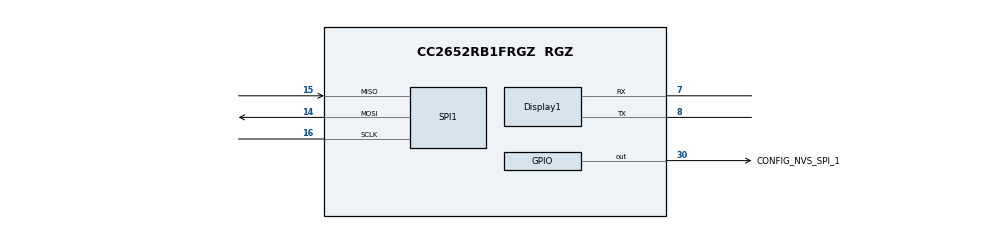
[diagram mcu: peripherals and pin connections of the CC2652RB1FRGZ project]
/**
 * @cliArgs --device "CC2652RB1FRGZ" --package "RGZ" --part "Default" --product "simplelink_cc13x2_26x2_sdk@5.10.00.48"
 * @versions {"data":"2021031521","timestamp":"2021031521","tool":"1.8.0+1863","templates":null}
 */

/**
 * Import the modules used in this configuration.
 */
const CCFG      = scripting.addModule("/ti/devices/CCFG");
const rfdesign  = scripting.addModule("/ti/devices/radioconfig/rfdesign");
const Display   = scripting.addModule("/ti/display/Display", {}, false);
const Display1  = Display.addInstance();
const AESCCM    = scripting.addModule("/ti/drivers/AESCCM");
const AESCCM1   = AESCCM.addInstance();
const AESECB    = scripting.addModule("/ti/drivers/AESECB");
const AESECB1   = AESECB.addInstance();
const Board     = scripting.addModule("/ti/drivers/Board");
const DMA       = scripting.addModule("/ti/drivers/DMA");
const ECDH      = scripting.addModule("/ti/drivers/ECDH");
const ECDH1     = ECDH.addInstance();
const ECDSA     = scripting.addModule("/ti/drivers/ECDSA");
const ECDSA1    = ECDSA.addInstance();
const ECJPAKE   = scripting.addModule("/ti/drivers/ECJPAKE");
const ECJPAKE1  = ECJPAKE.addInstance();
const NVS       = scripting.addModule("/ti/drivers/NVS");
const NVS1      = NVS.addInstance();
const NVS2      = NVS.addInstance();
const Power     = scripting.addModule("/ti/drivers/Power");
const RF        = scripting.addModule("/ti/drivers/RF");
const SHA2      = scripting.addModule("/ti/drivers/SHA2");
const SHA21     = SHA2.addInstance();
const SPI       = scripting.addModule("/ti/drivers/SPI", {}, false);
const SPI1      = SPI.addInstance();
const TRNG      = scripting.addModule("/ti/drivers/TRNG");
const TRNG1     = TRNG.addInstance();
const Watchdog  = scripting.addModule("/ti/drivers/Watchdog");
const Watchdog1 = Watchdog.addInstance();
const thread    = scripting.addModule("/ti/thread/thread");
const JSON      = scripting.addModule("/ti/utils/JSON");

/**
 * Write custom configuration values to the imported modules.
 */
CCFG.enableBootloader         = true;
CCFG.enableBootloaderBackdoor = true;
CCFG.dioBootloaderBackdoor    = 13;
CCFG.levelBootloaderBackdoor  = "Active low";
CCFG.srcClkLF                 = "LF RCOSC";
CCFG.enableCodeGeneration     = false;
CCFG.ccfgTemplate.$name       = "ti_devices_CCFGTemplateInit0";

Display1.$name                    = "CONFIG_DISPLAY_UART";
Display1.uart.$name               = "CONFIG_UART_0";
Display1.uart.uart.txPin.$assign  = "8";
Display1.uart.uart.rxPin.$assign  = "7";
Display1.uart.txPinInstance.$name = "CONFIG_PIN_1";
Display1.uart.rxPinInstance.$name = "CONFIG_PIN_2";

AESCCM1.$name = "CONFIG_AESCCM_0";

AESECB1.$name = "CONFIG_AESECB_0";

Board.generateInitializationFunctions = false;

ECDH1.$name = "CONFIG_ECDH_0";

ECDSA1.$name = "CONFIG_ECDSA_0";

ECJPAKE1.$name = "CONFIG_ECJPAKE_0";

NVS1.$name                    = "CONFIG_NVSINTERNAL";
NVS1.internalFlash.$name      = "ti_drivers_nvs_NVSCC26XX0";
NVS1.internalFlash.regionBase = 0x52000;
NVS1.internalFlash.regionSize = 0x4000;

NVS2.$name                          = "CONFIG_NVS_EXTERNAL";
NVS2.nvsType                        = "External";
NVS2.externalFlash.$name            = "ti_drivers_nvs_NVSSPI25X1";
NVS2.externalFlash.regionSize       = 0x128000;
NVS2.externalFlash.verifyBufferSize = 64;

SHA21.$name = "CONFIG_SHA2_0";

TRNG1.$name = "CONFIG_TRNG_0";

Watchdog1.$name            = "CONFIG_WATCHDOG0";
Watchdog1.watchdog.$assign = "WDT0";

const NVSSPI25XDevice                                      = scripting.addModule("/ti/drivers/nvs/NVSSPI25XDevice", {}, false);
const NVSSPI25XDevice1                                     = NVSSPI25XDevice.addInstance({}, false);
NVSSPI25XDevice1.$name                                     = "CONFIG_NVS_SPI_1";
NVS2.externalFlash.spiFlashDevice                          = NVSSPI25XDevice1;
NVSSPI25XDevice1.slaveSelectGpioInstance.$name             = "CONFIG_GPIO_CS_FLASH";
NVSSPI25XDevice1.slaveSelectGpioInstance.mode              = "Dynamic";
NVSSPI25XDevice1.slaveSelectGpioInstance.gpioPin.$assign   = "30";
NVSSPI25XDevice1.slaveSelectGpioInstance.pinInstance.$name = "CONFIG_PIN_4";
NVSSPI25XDevice1.slaveSelectGpioInstance.pinInstance.pull  = "Pull Up";

NVSSPI25XDevice1.sharedSpiInstance = SPI1;
SPI1.$name                         = "CONFIG_SPI_FLASH";
SPI1.spi.$assign                   = "SSI0";
SPI1.spi.sclkPin.$assign           = "16";
SPI1.spi.misoPin.$assign           = "15";
SPI1.spi.mosiPin.$assign           = "14";
SPI1.spi.dmaRxChannel.$assign      = "DMA_CH3";
SPI1.spi.dmaTxChannel.$assign      = "DMA_CH4";
SPI1.sclkPinInstance.$name         = "CONFIG_PIN_0";
SPI1.misoPinInstance.$name         = "CONFIG_PIN_5";
SPI1.mosiPinInstance.$name         = "CONFIG_PIN_6";

thread.deviceType                            = "mtd";
thread.deviceTypeReadOnly                    = true;
thread.pm.$name                              = "ti_thread_pm_thread_pm0";
thread.pm.pollPeriod                         = 60000;
thread.rf.$name                              = "ti_thread_rf_thread_rf0";
thread.rf.radioConfig.$name                  = "ti_devices_radioconfig_settings_ieee_15_40";
thread.rf.radioConfig.codeExportConfig.$name = "ti_devices_radioconfig_code_export_param0";
thread.network.$name                         = "ti_thread_network_thread_network0";
thread.network.panID                         = "0xFace";
thread.network.extPanID                      = "0xDEAD00BEEF00CAFE";
thread.network.setNetwork                    = false;
thread.security.$name                        = "ti_thread_security_thread_security0";
thread.security.pskd                         = "SLA3SH";

/**
 * Pinmux solution for unlocked pins/peripherals. This ensures that minor changes to the automatic solver in a future
 * version of the tool will not impact the pinmux you originally saw.  These lines can be completely deleted in order to
 * re-solve from scratch.
 */
Display1.uart.uart.$suggestSolution = "UART1";
